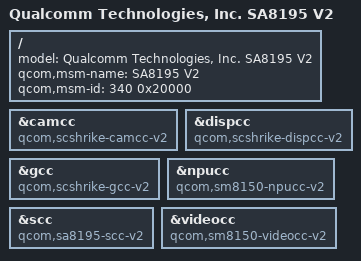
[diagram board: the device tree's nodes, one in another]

#include "sdmshrike.dtsi"
/ {
	model = "Qualcomm Technologies, Inc. SA8195 V2";
	qcom,msm-name = "SA8195 V2";
	qcom,msm-id = <340 0x20000>;
};

/delete-node/ &ufs_card_gdsc;

&camcc {
	compatible = "qcom,scshrike-camcc-v2", "syscon";
};

&dispcc {
	compatible = "qcom,scshrike-dispcc-v2", "syscon";
};

&gcc {
	compatible = "qcom,scshrike-gcc-v2", "syscon";
};

&npucc {
	compatible = "qcom,sm8150-npucc-v2", "syscon";
};

&scc {
	compatible = "qcom,sa8195-scc-v2", "syscon";
};

&videocc {
	compatible = "qcom,sm8150-videocc-v2", "syscon";
};
